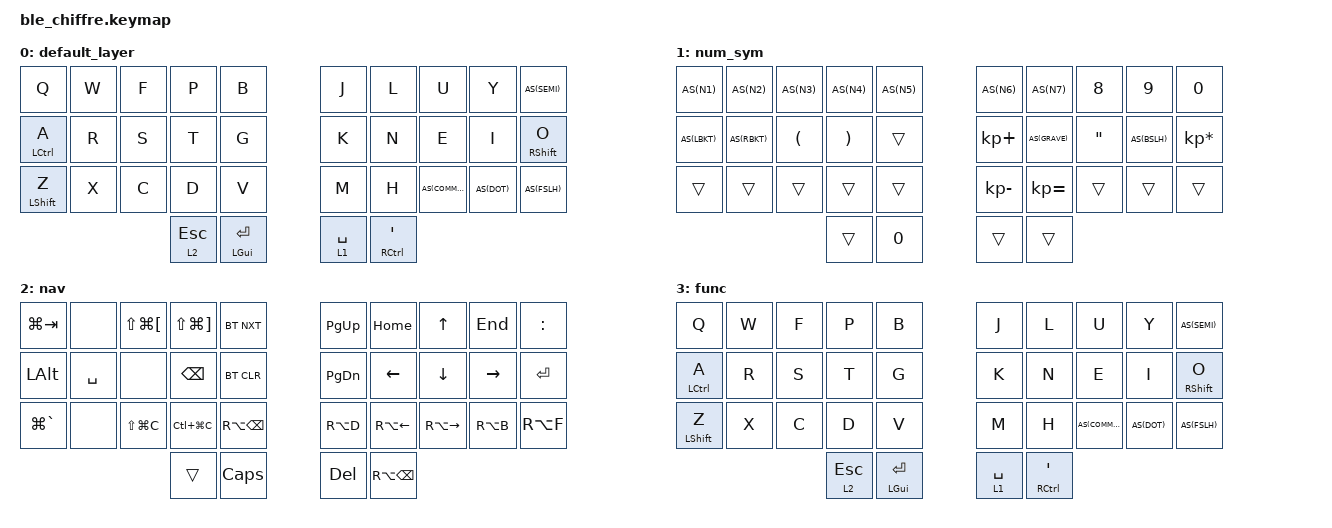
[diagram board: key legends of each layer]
/*
 * Copyright (c) 2020 The ZMK Contributors
 *
 * SPDX-License-Identifier: MIT
 */

#include <behaviors.dtsi>
#include <dt-bindings/zmk/keys.h>
#include <dt-bindings/zmk/bt.h>
#include <dt-bindings/zmk/rgb.h>

#define DEFAULT 0
#define NUM_SYM 1
#define NAV     2
#define FUNC    3
#define AS(keycode) &as LS(keycode) keycode     // Autoshift Macro

/ {
	behaviors {
		rst: boot_reset
		{
			compatible = "zmk,behavior-hold-tap";
			label = "Bootloader Tap - Reset Hold";
			#binding-cells = <2>;
			tapping_term_ms = <200>;
            flavor = "balanced";
			bindings = <&sys_reset>, <&bootloader>;
        };

        as: auto_shift {
            compatible = "zmk,behavior-hold-tap";
            label = "AUTO_SHIFT";
            #binding-cells = <2>;
            tapping_term_ms = <135>;
            quick_tap_ms = <0>;
            flavor = "tap-preferred";
            bindings = <&kp>, <&kp>;
        };

        bh: layer_taps
		{
			compatible = "zmk,behavior-hold-tap";
			label = "Layer-Tap";
			#binding-cells = <2>;
			tapping_term_ms = <215>;
            flavor = "tap-preferred";
			bindings = <&mo>, <&kp>;
        };

        hm: homerow_mods0
		{
			compatible = "zmk,behavior-hold-tap";
			label = "homerow mods";
			#binding-cells = <2>;
			tapping_term_ms = <200>;
            quick-tap-ms = <125>;
            global-quick-tap;
            flavor = "tap-preferred";
			bindings = <&kp>, <&kp>;
        };

        com_col: comma_semicolon
		{
		 	compatible = "zmk,behavior-hold-tap";
	     	label = "Tap comma_hold colon";
			#binding-cells = <2>;
			tapping_term_ms = <150>;
            flavor = "balanced";
		 	bindings = <&kp>, <&kp>;
	    };
   	 };
};

/ {
	combos {
		compatible = "zmk,combos";
		combo_backspce {
			timeout-ms = <50>;
			key-positions = <8 9>;
			bindings = <&kp BSPC>;
		};
		combo_tab
		{
			timeout-ms = <35>;
			key-positions = <11 12>;
			bindings = <&kp TAB>;
		};
		combo_minus
		{
			timeout-ms = <30>;
			key-positions = <26 27>;
			bindings = <AS(MINUS)>;
		};
		combo_dollar
		{
			timeout-ms = <30>;
			key-positions = <25 26>;
			bindings = <&kp DLLR>;
		};
		combo_gz
		{
			timeout-ms = <30>;
			key-positions = <20 21>;
			bindings = <&kp LG(Z)>;
		};
		combo_gx
		{
			timeout-ms = <30>;
			key-positions = <21 22>;
			bindings = <&kp LG(X)>;
		};
		combo_gc
		{
			timeout-ms = <40>;
			key-positions = <22 23>;
			bindings = <&kp LG(C)>;
		};
		combo_gv
		{
			timeout-ms = <30>;
			key-positions = <23 24>;
			bindings = <&kp LG(V)>;
		};
		combo_ent
		{
			timeout-ms = <30>;
			key-positions = <17 18>;
			bindings = <&kp RET>;
		};
	};
};

/ {
    keymap
	{
    compatible = "zmk,keymap";

    default_layer {
            bindings = <
    &kp Q &kp W &kp F &kp P &kp B &kp J &kp L &kp U &kp Y AS(SEMI)
    &hm LCTRL A &kp R &kp S &kp T &kp G &kp K &kp N &kp E &kp I &hm RSHFT O
    &hm LSHFT Z &kp X &kp C &kp D &kp V &kp M &kp H AS(COMMA) AS(DOT) AS(FSLH)
    &bh 2 ESC &mt LGUI RET &bh 1 SPACE &mt RCTRL SQT
            >;
        };

    num_sym {
            bindings = <
    AS(N1) AS(N2) AS(N3) AS(N4) AS(N5) AS(N6) AS(N7) &kp N8 &kp N9 &kp N0
    AS(LBKT) AS(RBKT) &kp LPAR &kp RPAR &trans &kp KP_PLUS AS(GRAVE) &kp DQT AS(BSLH) &kp KP_ASTERISK
    &trans &trans &trans &trans &trans &kp KP_MINUS &kp KP_EQUAL &trans &trans &trans
    &trans &kp N0 &trans &trans
            >;
        };

    nav {
            bindings = <
    &kp LG(TAB) &none     &kp LS(LG(LBKT)) &kp LS(LG(RBKT)) &bt BT_NXT	&kp PG_UP &kp HOME &kp UP   &kp END   &kp COLON
    &kp LALT    &kp SPACE &none            &kp BSPC         &bt BT_CLR  &kp PG_DN &kp LEFT &kp DOWN &kp RIGHT &kp RET
    &kp LG(GRAVE) &none &kp LS(LG(C))      &kp LC(LG(C))    &kp RA(BSPC) &kp RA(D) &kp RA(LEFT) &kp RA(RIGHT) &kp RA(B) &kp RA(F)
    &trans &kp CAPS &kp DEL &kp RA(BSPC)
            >;
        };

    func {
            bindings = <
    &kp Q &kp W &kp F &kp P &kp B &kp J &kp L &kp U &kp Y AS(SEMI)
    &hm LCTRL A &kp R &kp S &kp T &kp G &kp K &kp N &kp E &kp I &hm RSHFT O
    &hm LSHFT Z &kp X &kp C &kp D &kp V &kp M &kp H AS(COMMA) AS(DOT) AS(FSLH)
    &bh 2 ESC &mt LGUI RET &bh 1 SPACE &mt RCTRL SQT
            >;
        };

    };
};
